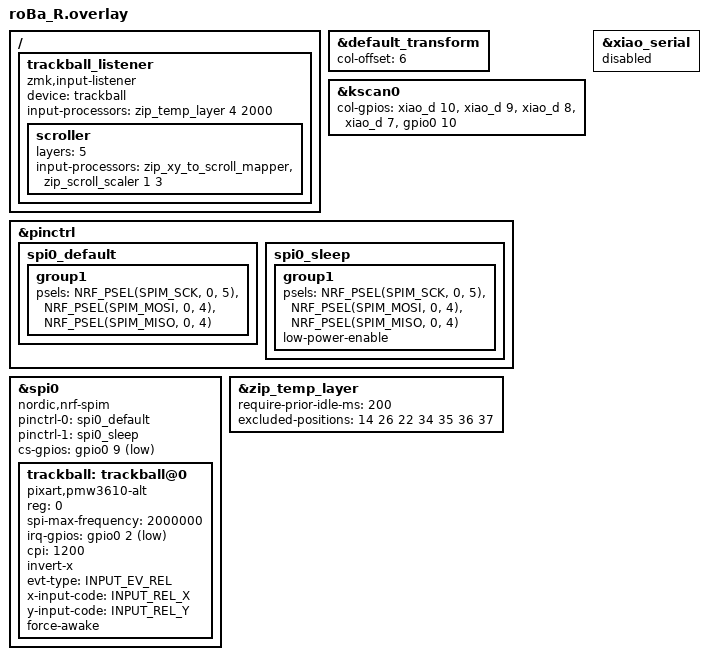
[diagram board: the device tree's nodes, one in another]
#include "roBa.dtsi"
#include <zephyr/dt-bindings/input/input-event-codes.h>
#include <input/processors.dtsi>

&default_transform {
    col-offset = <6>;
};

&kscan0 {
        col-gpios
            = <&xiao_d 10 GPIO_ACTIVE_HIGH>
            , <&xiao_d 9 GPIO_ACTIVE_HIGH>
            , <&xiao_d 8 GPIO_ACTIVE_HIGH>
            , <&xiao_d 7 GPIO_ACTIVE_HIGH>
            , <&gpio0 10 GPIO_ACTIVE_HIGH>
            ;
};

/ {
    trackball_listener {
        status = "okay";
        compatible = "zmk,input-listener";
        device = <&trackball>;

        // AML：軌跡球移動 → MOUSE 層（Layer 4），2 秒後退出
        input-processors = <&zip_temp_layer 4 2000>;

        // SCROLL 層（Layer 5）啟用時軌跡球變捲輪
        scroller {
            layers = <5>;
            input-processors =
                <&zip_xy_to_scroll_mapper>,
                <&zip_scroll_scaler 1 3>;
        };
    };
};

&pinctrl {
    spi0_default: spi0_default {
        group1 {
            psels = <NRF_PSEL(SPIM_SCK, 0, 5)>,
                <NRF_PSEL(SPIM_MOSI, 0, 4)>,
                <NRF_PSEL(SPIM_MISO, 0, 4)>;
        };
    };

    spi0_sleep: spi0_sleep {
        group1 {
            psels = <NRF_PSEL(SPIM_SCK, 0, 5)>,
                <NRF_PSEL(SPIM_MOSI, 0, 4)>,
                <NRF_PSEL(SPIM_MISO, 0, 4)>;
            low-power-enable;
        };
    };
};

&xiao_serial { status = "disabled"; };

&spi0 {
    status = "okay";
    compatible = "nordic,nrf-spim";
    pinctrl-0 = <&spi0_default>;
    pinctrl-1 = <&spi0_sleep>;
    pinctrl-names = "default", "sleep";
    cs-gpios = <&gpio0 9 GPIO_ACTIVE_LOW>;

    trackball: trackball@0 {
        status = "okay";
        compatible = "pixart,pmw3610-alt";
        reg = <0>;
        spi-max-frequency = <2000000>;
        irq-gpios = <&gpio0 2 (GPIO_ACTIVE_LOW | GPIO_PULL_UP)>;
        cpi = <1200>;
        invert-x;
        evt-type = <INPUT_EV_REL>;
        x-input-code = <INPUT_REL_X>;
        y-input-code = <INPUT_REL_Y>;
        force-awake;
    };
};

/* AML 防誤觸：G/B 滑鼠鍵 + 修飾鍵不退出 MOUSE 層（對照 moNa2） */
&zip_temp_layer {
    require-prior-idle-ms = <200>;
    excluded-positions = < 14 /* G = MB1 */
                           26 /* B = MB2 */
                           22 /* Z = Shift (mod-tap) */
                           34 /* LEFT_SHIFT (thumb) */
                           35 /* LCTRL (thumb) */
                           36 /* LEFT_ALT (thumb) */
                           37 /* LEFT_COMMAND (thumb) */ >;
};
